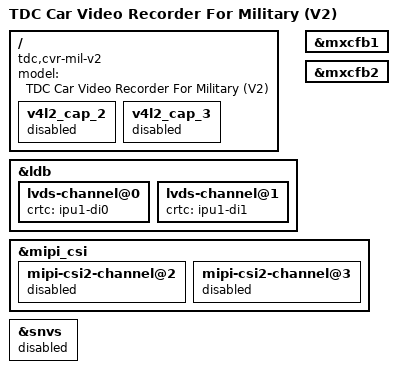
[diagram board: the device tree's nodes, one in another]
/*
 * Technology Development Co.,Ltd
 * http://www.nedi.com.cn
 * Varphone Wong <varphone@qq.com>
 */

/dts-v1/;
#include "imx6dl.dtsi"
#include "myimx6ek200-cm.dtsi"

/ {
	model = "TDC Car Video Recorder For Military (V2)";
	compatible = "tdc,cvr-mil-v2", "myzr,myimx6", "myzr,myimx6u", "myzr,myimx6cb200", "myzr,myimx6ek200", "fsl,imx6dl", "fsl,imx6dl-ldb";

	v4l2_cap_2 {
		status = "disabled";
	};

	v4l2_cap_3 {
		status = "disabled";
	};
};

&ldb {
	lvds-channel@0 {
		crtc = "ipu1-di0";
	};
	lvds-channel@1 {
		crtc = "ipu1-di1";
	};
};

&mxcfb1 {
	status = "okay";
};

&mxcfb2 {
	status = "okay";
};

&mipi_csi {
	mipi-csi2-channel@2 {
		status = "disabled";
	};

	mipi-csi2-channel@3 {
		status = "disabled";
	};
};

&snvs {
	status = "disabled";
};
